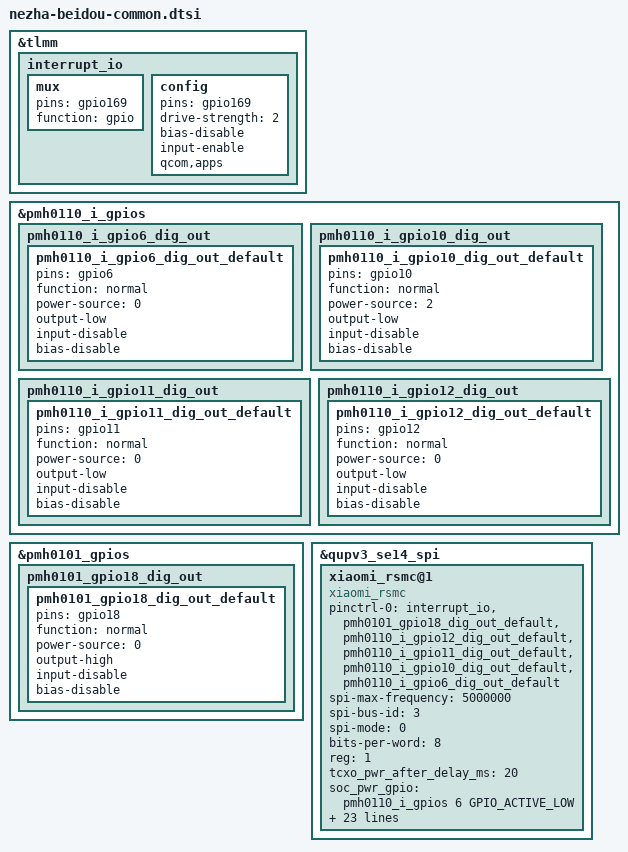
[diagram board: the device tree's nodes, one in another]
&tlmm {
        interrupt_io: interrupt_io {
		mux {
			pins = "gpio169";
			function = "gpio";
		};

		config {
			pins = "gpio169";
			drive-strength = <2>;
			bias-disable;
			input-enable;
			qcom,apps;
		};
	};
};

&pmh0110_i_gpios {
    pmh0110_i_gpio6_dig_out {
        pmh0110_i_gpio6_dig_out_default: pmh0110_i_gpio6_dig_out_default {
            pins = "gpio6";
            function = "normal";
            power-source = <0>; /* 1.8v */
            output-low;
            input-disable;
            bias-disable;
        };
    };
    pmh0110_i_gpio10_dig_out {
        pmh0110_i_gpio10_dig_out_default: pmh0110_i_gpio10_dig_out_default {
            pins = "gpio10";
            function = "normal";
            power-source = <2>; /* 1.2v */
            output-low;
            input-disable;
            bias-disable;
        };
    };
    pmh0110_i_gpio11_dig_out {
        pmh0110_i_gpio11_dig_out_default: pmh0110_i_gpio11_dig_out_default {
            pins = "gpio11";
            function = "normal";
            power-source = <0>; /* 1.8v */
            output-low;
            input-disable;
            bias-disable;
        };
    };
    pmh0110_i_gpio12_dig_out {
        pmh0110_i_gpio12_dig_out_default: pmh0110_i_gpio12_dig_out_default {
            pins = "gpio12";
            function = "normal";
            power-source = <0>; /* 1.8v */
            output-low;
            input-disable;
            bias-disable;
        };
    };
};

&pmh0101_gpios {
    pmh0101_gpio18_dig_out {
        pmh0101_gpio18_dig_out_default: pmh0101_gpio18_dig_out_default {
            pins = "gpio18";
            function = "normal";
            power-source = <0>; /* 1.8v */
            output-high;
            input-disable;
            bias-disable;
        };
    };
};

&qupv3_se14_spi {
        //pinctrl-0 = <&interrupt_io>;
        //pinctrl-1 = <&mi_qupv3_se10_spi_sleep>, <&mi_qupv3_se10_spi_cs_sleep>;
        //pinctrl-0 = <&mi_se13_spi_mosi_active>, <&mi_se13_spi_miso_active>,<&mi_se13_spi_clk_active>,<&mi_se13_spi_cs_active>;
        //pinctrl-1 = <&mi_qupv3_se10_spi_sleep>, <&mi_qupv3_se10_spi_cs_sleep>;
        xiaomi_rsmc@1 {
        	pinctrl-0 = <&interrupt_io>,<&pmh0101_gpio18_dig_out_default>,<&pmh0110_i_gpio12_dig_out_default>,
                    <&pmh0110_i_gpio11_dig_out_default>,<&pmh0110_i_gpio10_dig_out_default>,<&pmh0110_i_gpio6_dig_out_default>;
        	pinctrl-names = "default";
		compatible = "xiaomi_rsmc";
		status = "ok";
		/* SPI Config */
		spi-max-frequency = <5000000>;
		spi-bus-id = <3>;
		spi-mode = <0>;
		bits-per-word = <8>;
		reg = <1>;
		/* Timing */
		tcxo_pwr_after_delay_ms = <20>;
                
		/* GPIO Config */
		soc_pwr_gpio = <&pmh0110_i_gpios 6 GPIO_ACTIVE_LOW>;
		en_gpio = <&pmh0110_i_gpios 11 GPIO_ACTIVE_LOW>;
		mcu_rst_gpio = <&pmh0110_i_gpios 12 GPIO_ACTIVE_LOW>;
		interrupt-parent = <&tlmm>;
		interrupts = <169 0x2000>;
		irq_gpio = <&tlmm 169 0x2000>;
		rx_ant_gpio = <&pmh0101_gpios 18 GPIO_ACTIVE_LOW>;
		rsmc_vc1_ant_gpio = <&pmh0110_d_gpios 13 GPIO_ACTIVE_HIGH>;
		rsmc_vc2_ant_gpio = <&pmh0110_d_gpios 14 GPIO_ACTIVE_LOW>;
		rd_ls_gpio = <&pmh0110_i_gpios 10 GPIO_ACTIVE_LOW>;

		/* Feature Config */
		cpu-affinity-offset = <0>;
		cpu-affinity-mask = <112>;
                rsmc_vc1_default_value = <1>;
                rsmc_vc2_default_value = <0>;
		/* Power Config */
		rsmc-tcxo-vcc-type = <1>;
                rsmc-pa-dcdc-supply = <&hl7603_regulator_l1>;
		rsmc-tcxo-vcc-value = <1800000>;
		rsmc_enable_x801;
		rf_file_name = "/odm/etc/rsmc/rf-para/rf.json";
		config_name = "default";
		tcxo_frequency = <1>;
	};
};
